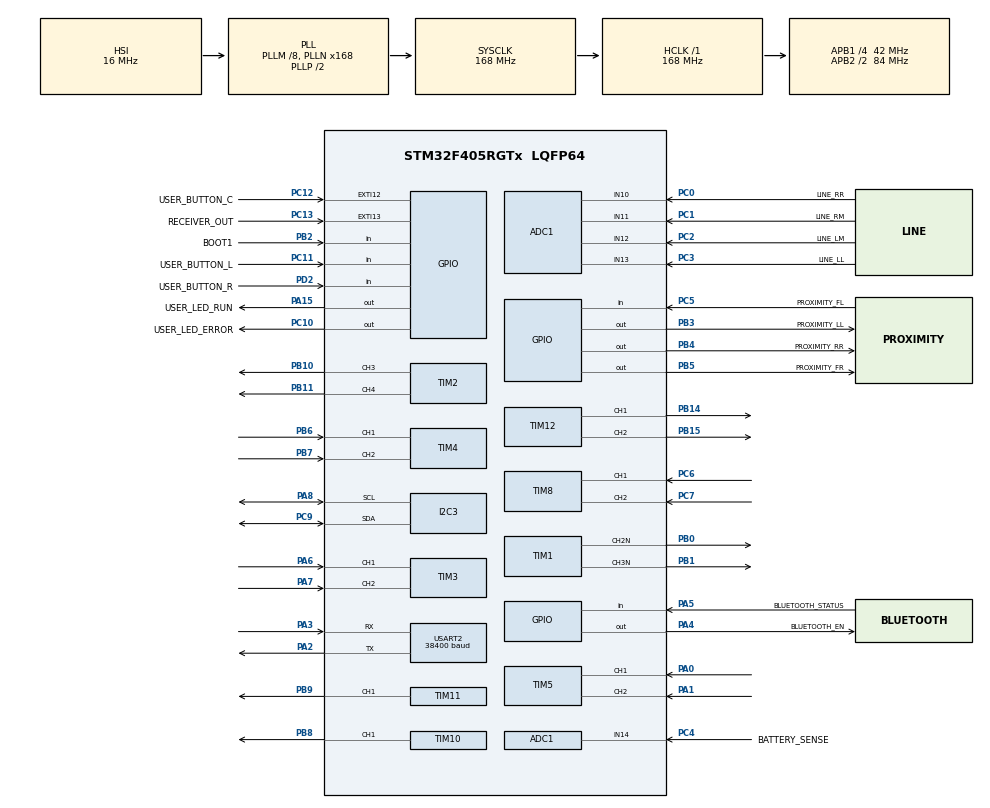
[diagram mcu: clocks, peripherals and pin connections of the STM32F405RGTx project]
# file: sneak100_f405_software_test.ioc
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Mcu.Family=STM32F4
RCC.CortexFreq_Value=168000000
VP_ADC1_TempSens_Input.Mode=IN-TempSens
ADC1.ContinuousConvMode=ENABLE
TIM12.Channel-PWM\ Generation2\ CH2=TIM_CHANNEL_2
PC10.Signal=GPIO_Output
PC12.Signal=GPXTI12
SH.S_TIM5_CH2.0=TIM5_CH2,Encoder_Interface
PC0.GPIO_Label=LINE_RR
PB11.Signal=S_TIM2_CH4
PB15.Signal=S_TIM12_CH2
RCC.SYSCLKSource=RCC_SYSCLKSOURCE_PLLCLK
ProjectManager.StackSize=0x400
PA15.GPIO_Label=USER_LED_RUN
ADC1.Channel-3\#ChannelRegularConversion=ADC_CHANNEL_13
RCC.HCLKFreq_Value=168000000
RCC.APB2TimFreq_Value=168000000
PB6.Signal=S_TIM4_CH1
VP_TIM10_VS_ClockSourceINT.Mode=Enable_Timer
Dma.ADC1.0.Direction=DMA_PERIPH_TO_MEMORY
ADC1.Channel-2\#ChannelRegularConversion=ADC_CHANNEL_12
PC7.Signal=S_TIM8_CH2
PC3.Signal=ADCx_IN13
NVIC.DMA2_Stream0_IRQn=true\:0\:0\:false\:false\:true\:false\:true
Dma.ADC1.0.MemDataAlignment=DMA_MDATAALIGN_HALFWORD
RCC.AHBFreq_Value=168000000
ADC1.Channel-0\#ChannelRegularConversion=ADC_CHANNEL_10
RCC.HSE_VALUE=8000000
PB2.Signal=GPIO_Input
ADC1.ScanConvMode=ENABLE
PC13-ANTI_TAMP.Signal=GPXTI13
TIM10.Channel=TIM_CHANNEL_1
ADC1.SamplingTime-4\#ChannelRegularConversion=ADC_SAMPLETIME_480CYCLES
ADC1.Rank-2\#ChannelRegularConversion=3
SH.S_TIM12_CH1.0=TIM12_CH1,PWM Generation1 CH1
PC4.GPIO_Label=BATTERY_SENSE
PA14.Mode=Serial_Wire
Dma.ADC1.0.PeriphInc=DMA_PINC_DISABLE
PC11.GPIO_Label=USER_BUTTON_L
PC9.Mode=I2C
SH.S_TIM4_CH2.0=TIM4_CH2,Encoder_Interface
PB7.Signal=S_TIM4_CH2
PA8.Signal=I2C3_SCL
SH.S_TIM3_CH1.0=TIM3_CH1,Encoder_Interface
ADC1.SamplingTime-0\#ChannelRegularConversion=ADC_SAMPLETIME_56CYCLES
Mcu.Package=LQFP64
PB9.Signal=S_TIM11_CH1
PB1.Signal=TIM1_CH3N
PA6.Signal=S_TIM3_CH1
SH.ADCx_IN14.0=ADC1_IN14,IN14
USART2.VirtualMode=VM_ASYNC
SH.S_TIM10_CH1.0=TIM10_CH1,PWM Generation1 CH1
PA15.Signal=GPIO_Output
SH.S_TIM12_CH2.0=TIM12_CH2,PWM Generation2 CH2
RCC.APB2CLKDivider=RCC_HCLK_DIV2
PB5.GPIO_Label=PROXIMITY_FR
SH.S_TIM4_CH1.0=TIM4_CH1,Encoder_Interface
RCC.APB1TimFreq_Value=84000000
SH.S_TIM5_CH1.0=TIM5_CH1,Encoder_Interface
Dma.ADC1.0.FIFOMode=DMA_FIFOMODE_DISABLE
PC5.Signal=GPIO_Input
TIM1.Channel-Output\ Compare2\ CH2N=TIM_CHANNEL_2
SH.S_TIM11_CH1.0=TIM11_CH1,PWM Generation1 CH1
Dma.Request0=ADC1
PA4.GPIO_Label=BLUETOOTH_EN
PC2.GPIO_Label=LINE_LM
ADC1.Rank-4\#ChannelRegularConversion=5
PB4.Signal=GPIO_Output
PA3.Signal=USART2_RX
PB3.GPIO_Label=PROXIMITY_LL
I2C3.I2C_Mode=I2C_Fast
TIM2.Channel-PWM\ Generation4\ CH4=TIM_CHANNEL_4
SH.ADCx_IN13.0=ADC1_IN13,IN13
Dma.ADC1.0.Instance=DMA2_Stream0
ADC1.Rank-0\#ChannelRegularConversion=1
ADC1.Channel-4\#ChannelRegularConversion=ADC_CHANNEL_14
PC10.GPIO_Label=USER_LED_ERROR
PC13-ANTI_TAMP.GPIO_Label=RECEIVER_OUT
PC11.Signal=GPIO_Input
PC2.Signal=ADCx_IN12
PC4.Signal=ADCx_IN14
PC6.Signal=S_TIM8_CH1
PC0.Signal=ADCx_IN10
RCC.APB1CLKDivider=RCC_HCLK_DIV4
NVIC.USART2_IRQn=true\:0\:0\:false\:false\:true\:true\:true
USART2.BaudRate=38400
SH.S_TIM8_CH2.0=TIM8_CH2,Encoder_Interface
ADC1.SamplingTime-2\#ChannelRegularConversion=ADC_SAMPLETIME_56CYCLES
PA0-WKUP.Signal=S_TIM5_CH1
VP_TIM11_VS_ClockSourceINT.Mode=Enable_Timer
ADC1.Channel-7\#ChannelRegularConversion=ADC_CHANNEL_TEMPSENSOR
PA3.Mode=Asynchronous
PA13.Signal=SYS_JTMS-SWDIO
Dma.ADC1.0.PeriphDataAlignment=DMA_PDATAALIGN_HALFWORD
SH.ADCx_IN12.0=ADC1_IN12,IN12
ProjectManager.TargetToolchain=STM32CubeIDE
Dma.ADC1.0.Mode=DMA_CIRCULAR
Dma.ADC1.0.Priority=DMA_PRIORITY_LOW
ADC1.Channel-1\#ChannelRegularConversion=ADC_CHANNEL_11
TIM1.Channel-Output\ Compare3\ CH3N=TIM_CHANNEL_3
RCC.LSE_VALUE=32768
PA1.Signal=S_TIM5_CH2
PB10.Signal=S_TIM2_CH3
PB14.Signal=S_TIM12_CH1
PA5.Signal=GPIO_Input
SH.S_TIM3_CH2.0=TIM3_CH2,Encoder_Interface
SH.S_TIM8_CH1.0=TIM8_CH1,Encoder_Interface
PB0.Mode=Output Compare2 CH2N
board=custom
RCC.VCOOutputFreq_Value=336000000
TIM12.Channel-PWM\ Generation1\ CH1=TIM_CHANNEL_1
RCC.APB2Freq_Value=84000000
SH.ADCx_IN11.0=ADC1_IN11,IN11
PB4.GPIO_Label=PROXIMITY_RR
SH.S_TIM2_CH3.0=TIM2_CH3,PWM Generation3 CH3
PC1.GPIO_Label=LINE_RM
TIM2.Channel-PWM\ Generation3\ CH3=TIM_CHANNEL_3
ADC1.DMAContinuousRequests=ENABLE
ADC1.NbrOfConversion=6
PA13.Mode=Serial_Wire
Mcu.Name=STM32F405RGTx
PA2.Signal=USART2_TX
RCC.48MHZClocksFreq_Value=48000000
PB3.Signal=GPIO_Output
PA4.Signal=GPIO_Output
ADC1.SamplingTime-1\#ChannelRegularConversion=ADC_SAMPLETIME_56CYCLES
RCC.SYSCLKFreq_VALUE=168000000
PB5.Signal=GPIO_Output
ADC1.master=1
PA5.GPIO_Label=BLUETOOTH_STATUS
ADC1.Rank-3\#ChannelRegularConversion=4
ADC1.SamplingTime-3\#ChannelRegularConversion=ADC_SAMPLETIME_56CYCLES
PC5.GPIO_Label=PROXIMITY_FL
PC12.GPIO_Label=USER_BUTTON_C
ADC1.Rank-1\#ChannelRegularConversion=2
PA14.Signal=SYS_JTCK-SWCLK
Dma.ADC1.0.MemInc=DMA_MINC_ENABLE
PB2.GPIO_Label=BOOT1
SH.ADCx_IN10.0=ADC1_IN10,IN10
ProjectManager.HeapSize=0x200
PB1.Mode=Output Compare3 CH3N
SH.S_TIM2_CH4.0=TIM2_CH4,PWM Generation4 CH4
RCC.HSI_VALUE=16000000
ADC1.Rank-7\#ChannelRegularConversion=6
RCC.PLLQ=7
NVIC.PriorityGroup=NVIC_PRIORITYGROUP_4
ADC1.NbrOfConversionFlag=1
RCC.PLLM=8
RCC.PLLN=168
TIM11.Channel=TIM_CHANNEL_1
PA2.Mode=Asynchronous
PB8.Signal=S_TIM10_CH1
PC3.GPIO_Label=LINE_LL
PA8.Mode=I2C
PC9.Signal=I2C3_SDA
ADC1.SamplingTime-7\#ChannelRegularConversion=ADC_SAMPLETIME_480CYCLES
PD2.Signal=GPIO_Input
RCC.APB1Freq_Value=42000000
PB0.Signal=TIM1_CH2N
ADC1.ClockPrescaler=ADC_CLOCK_SYNC_PCLK_DIV4
PC1.Signal=ADCx_IN11
PD2.GPIO_Label=USER_BUTTON_R
PA7.Signal=S_TIM3_CH2

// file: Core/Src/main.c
/* USER CODE BEGIN Header */
/**
  ******************************************************************************
  * @file           : main.c
  * @brief          : Main program body
  ******************************************************************************
  * @attention
  *
  * <h2><center>&copy; Copyright (c) 2021 STMicroelectronics.
  * All rights reserved.</center></h2>
  *
  * This software component is licensed by ST under BSD 3-Clause license,
  * the "License"; You may not use this file except in compliance with the
  * License. You may obtain a copy of the License at:
  *                        opensource.org/licenses/BSD-3-Clause
  *
  ******************************************************************************
  */
/* USER CODE END Header */
#include "main.h"
#include "adc.h"
#include "i2c.h"
#include "tim.h"
#include "usart.h"
#include "gpio.h"

/* USER CODE BEGIN Includes */
#include "string.h"

#include "sneak100_motors.h"
#include "sneak100_display.h"
#include "sneak100_proximity.h"
#include "sneak100_bluetooth.h"
/* USER CODE END Includes */

void SystemClock_Config(void);
/* USER CODE BEGIN PFP */

void HAL_UART_RxCpltCallback(UART_HandleTypeDef *huart) {
	Bluetooth_RxCpltCallback(&bluetooth, huart);
}

/* USER CODE END PFP */

int main(void)
{

  /* MCU Configuration--------------------------------------------------------*/

  /* Reset of all peripherals, Initializes the Flash interface and the Systick. */
  HAL_Init();

  /* Configure the system clock */
  SystemClock_Config();

  /* Initialize all configured peripherals */
  MX_GPIO_Init();
  MX_TIM2_Init();
  MX_TIM3_Init();
  MX_TIM4_Init();
  MX_USART2_UART_Init();
  MX_ADC1_Init();
  MX_TIM8_Init();
  MX_I2C3_Init();
  MX_TIM12_Init();
  MX_TIM1_Init();
  MX_TIM5_Init();
  MX_TIM10_Init();
  MX_TIM11_Init();
  /* USER CODE BEGIN 2 */

  SNEAK100_Bluetooth_Init();
  //SNEAK100_Motors_Init();
  //SNEAK100_ProximitySensors_Init();
  //SNEAK100_Display_Init();

  /* USER CODE END 2 */

  /* Infinite loop */
  /* USER CODE BEGIN WHILE */
  while(1) {

	  if(Bluetooth_IsDataReady(&bluetooth)) {
		  uint8_t buffer[64] = {0};
		  Bluetooth_ReadData(&bluetooth, buffer);
		  //HAL_GPIO_TogglePin(USER_LED_RUN_GPIO_Port, USER_LED_RUN_Pin);

		  HAL_UART_Transmit(bluetooth.huart, buffer, strlen((char *)buffer), HAL_MAX_DELAY);
	  }

	  //gui.battery_voltage = rand()%1000/1000.f;

	  //SNEAK100_Display_Render();

	  //HAL_GPIO_TogglePin(USER_LED_RUN_GPIO_Port, USER_LED_RUN_Pin);
	  //HAL_Delay(100);

    /* USER CODE END WHILE */

  }
}

void SystemClock_Config(void)
{
  RCC_OscInitTypeDef RCC_OscInitStruct = {0};
  RCC_ClkInitTypeDef RCC_ClkInitStruct = {0};

  /** Configure the main internal regulator output voltage
  */
  __HAL_RCC_PWR_CLK_ENABLE();
  __HAL_PWR_VOLTAGESCALING_CONFIG(PWR_REGULATOR_VOLTAGE_SCALE1);
  /** Initializes the RCC Oscillators according to the specified parameters
  * in the RCC_OscInitTypeDef structure.
  */
  RCC_OscInitStruct.OscillatorType = RCC_OSCILLATORTYPE_HSI;
  RCC_OscInitStruct.HSIState = RCC_HSI_ON;
  RCC_OscInitStruct.HSICalibrationValue = RCC_HSICALIBRATION_DEFAULT;
  RCC_OscInitStruct.PLL.PLLState = RCC_PLL_ON;
  RCC_OscInitStruct.PLL.PLLSource = RCC_PLLSOURCE_HSI;
  RCC_OscInitStruct.PLL.PLLM = 8;
  RCC_OscInitStruct.PLL.PLLN = 168;
  RCC_OscInitStruct.PLL.PLLP = RCC_PLLP_DIV2;
  RCC_OscInitStruct.PLL.PLLQ = 7;
  if (HAL_RCC_OscConfig(&RCC_OscInitStruct) != HAL_OK)
  {
    Error_Handler();
  }
  /** Initializes the CPU, AHB and APB buses clocks
  */
  RCC_ClkInitStruct.ClockType = RCC_CLOCKTYPE_HCLK|RCC_CLOCKTYPE_SYSCLK
                              |RCC_CLOCKTYPE_PCLK1|RCC_CLOCKTYPE_PCLK2;
  RCC_ClkInitStruct.SYSCLKSource = RCC_SYSCLKSOURCE_PLLCLK;
  RCC_ClkInitStruct.AHBCLKDivider = RCC_SYSCLK_DIV1;
  RCC_ClkInitStruct.APB1CLKDivider = RCC_HCLK_DIV4;
  RCC_ClkInitStruct.APB2CLKDivider = RCC_HCLK_DIV2;

  if (HAL_RCC_ClockConfig(&RCC_ClkInitStruct, FLASH_LATENCY_5) != HAL_OK)
  {
    Error_Handler();
  }
}

void Error_Handler(void)
{
  __disable_irq();
  while (1)
  {
  }
}

/************************ (C) COPYRIGHT STMicroelectronics *****END OF FILE****/
